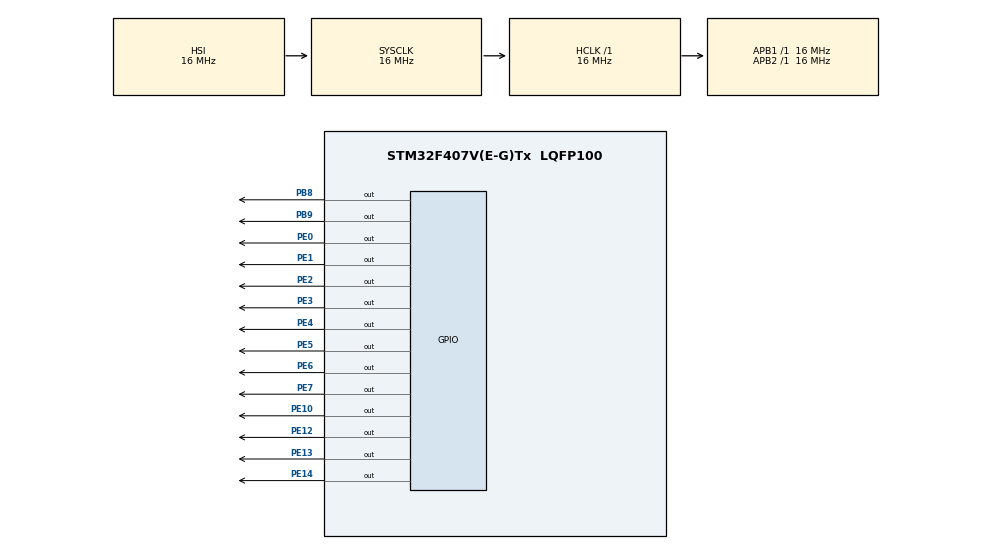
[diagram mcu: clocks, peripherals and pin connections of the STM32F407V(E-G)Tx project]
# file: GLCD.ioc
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Mcu.Family=STM32F4
Mcu.Name=STM32F407V(E-G)Tx
Mcu.Package=LQFP100
NVIC.PriorityGroup=NVIC_PRIORITYGROUP_4
PB8.Signal=GPIO_Output
PB9.Signal=GPIO_Output
PE0.Signal=GPIO_Output
PE1.Signal=GPIO_Output
PE10.Signal=GPIO_Output
PE12.Signal=GPIO_Output
PE13.Signal=GPIO_Output
PE14.Signal=GPIO_Output
PE2.Signal=GPIO_Output
PE3.Signal=GPIO_Output
PE4.Signal=GPIO_Output
PE5.Signal=GPIO_Output
PE6.Signal=GPIO_Output
PE7.Signal=GPIO_Output
PH0-OSC_IN.Mode=HSE-External-Oscillator
PH0-OSC_IN.Signal=RCC_OSC_IN
PH1-OSC_OUT.Mode=HSE-External-Oscillator
PH1-OSC_OUT.Signal=RCC_OSC_OUT
ProjectManager.HeapSize=0x200
ProjectManager.StackSize=0x400
ProjectManager.TargetToolchain=MDK-ARM V5.32
RCC.AHBFreq_Value=16000000
RCC.APB1Freq_Value=16000000
RCC.APB2Freq_Value=16000000
RCC.CortexFreq_Value=16000000
RCC.HSE_VALUE=8000000
RCC.HSI_VALUE=16000000
RCC.LSE_VALUE=32768
RCC.SYSCLKFreq_VALUE=16000000
RCC.VCOOutputFreq_Value=192000000
board=custom

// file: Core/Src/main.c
/* USER CODE BEGIN Header */
/**
 ******************************************************************************
 * @file           : main.c
 * @brief          : Main program body
 ******************************************************************************
 * @attention
 *
 * Copyright (c) 2025 STMicroelectronics.
 * All rights reserved.
 *
 * This software is licensed under terms that can be found in the LICENSE file
 * in the root directory of this software component.
 * If no LICENSE file comes with this software, it is provided AS-IS.
 *
 ******************************************************************************
 */
/* USER CODE END Header */
#include "main.h"

/* USER CODE BEGIN Includes */
#include "delay_fun.h"
#include "glcd2.h"

/* USER CODE END Includes */

/* USER CODE BEGIN PV */
extern const char img[1024];
extern const char img1[1024];
extern const char img2[1024];
extern const char img3[1024];
/* USER CODE END PV */

void SystemClock_Config(void);
static void MX_GPIO_Init(void);

int main(void)
{

	/* MCU Configuration--------------------------------------------------------*/

	/* Reset of all peripherals, Initializes the Flash interface and the Systick. */
	HAL_Init();

	/* Configure the system clock */
	SystemClock_Config();

	/* Initialize all configured peripherals */
	MX_GPIO_Init();
	/* USER CODE BEGIN 2 */
	TIM6Config();
	GLCD_Init();
	/* Initialize GLCD */
	GLCD_ClearAll();
	/* Clear all GLCD display */
	GLCD_String(0, "Microlab STM32f407 1403");
	/* Print String on 0th page of display
	 */
	HAL_Delay(2000);
	/* USER CODE END 2 */

	/* Infinite loop */
	/* USER CODE BEGIN WHILE */
	while (1)
	{
		// GLCD_Image(img);
		// HAL_Delay(500);
		// GLCD_Image(img1);
		// HAL_Delay(500);
		// GLCD_Image(img2);
		// HAL_Delay(500);
    GLCD_Image(img3);
		HAL_Delay(500);
		/* USER CODE END WHILE */

	}
}

void SystemClock_Config(void)
{
	RCC_OscInitTypeDef RCC_OscInitStruct = { 0 };
	RCC_ClkInitTypeDef RCC_ClkInitStruct = { 0 };

	/** Configure the main internal regulator output voltage
	 */
	__HAL_RCC_PWR_CLK_ENABLE();
	__HAL_PWR_VOLTAGESCALING_CONFIG(PWR_REGULATOR_VOLTAGE_SCALE1);

	/** Initializes the RCC Oscillators according to the specified parameters
	 * in the RCC_OscInitTypeDef structure.
	 */
	RCC_OscInitStruct.OscillatorType = RCC_OSCILLATORTYPE_HSI;
	RCC_OscInitStruct.HSIState = RCC_HSI_ON;
	RCC_OscInitStruct.HSICalibrationValue = RCC_HSICALIBRATION_DEFAULT;
	RCC_OscInitStruct.PLL.PLLState = RCC_PLL_NONE;
	if (HAL_RCC_OscConfig(&RCC_OscInitStruct) != HAL_OK)
	{
		Error_Handler();
	}

	/** Initializes the CPU, AHB and APB buses clocks
	 */
	RCC_ClkInitStruct.ClockType = RCC_CLOCKTYPE_HCLK | RCC_CLOCKTYPE_SYSCLK
		| RCC_CLOCKTYPE_PCLK1 | RCC_CLOCKTYPE_PCLK2;
	RCC_ClkInitStruct.SYSCLKSource = RCC_SYSCLKSOURCE_HSI;
	RCC_ClkInitStruct.AHBCLKDivider = RCC_SYSCLK_DIV1;
	RCC_ClkInitStruct.APB1CLKDivider = RCC_HCLK_DIV1;
	RCC_ClkInitStruct.APB2CLKDivider = RCC_HCLK_DIV1;

	if (HAL_RCC_ClockConfig(&RCC_ClkInitStruct, FLASH_LATENCY_0) != HAL_OK)
	{
		Error_Handler();
	}
}

static void MX_GPIO_Init(void)
{
	GPIO_InitTypeDef GPIO_InitStruct = { 0 };

	/* GPIO Ports Clock Enable */
	__HAL_RCC_GPIOE_CLK_ENABLE();
	__HAL_RCC_GPIOH_CLK_ENABLE();
	__HAL_RCC_GPIOB_CLK_ENABLE();

	/*Configure GPIO pin Output Level */
	HAL_GPIO_WritePin(GPIOE, GPIO_PIN_2 | GPIO_PIN_3 | GPIO_PIN_4 | GPIO_PIN_5 | GPIO_PIN_6 | GPIO_PIN_7 | GPIO_PIN_10 | GPIO_PIN_12 | GPIO_PIN_13 | GPIO_PIN_14 | GPIO_PIN_0 | GPIO_PIN_1, GPIO_PIN_RESET);

	/*Configure GPIO pin Output Level */
	HAL_GPIO_WritePin(GPIOB, GPIO_PIN_8 | GPIO_PIN_9, GPIO_PIN_RESET);

	/*Configure GPIO pins : PE2 PE3 PE4 PE5
							 PE6 PE7 PE10 PE12
							 PE13 PE14 PE0 PE1 */
	GPIO_InitStruct.Pin = GPIO_PIN_2 | GPIO_PIN_3 | GPIO_PIN_4 | GPIO_PIN_5
		| GPIO_PIN_6 | GPIO_PIN_7 | GPIO_PIN_10 | GPIO_PIN_12
		| GPIO_PIN_13 | GPIO_PIN_14 | GPIO_PIN_0 | GPIO_PIN_1;
	GPIO_InitStruct.Mode = GPIO_MODE_OUTPUT_PP;
	GPIO_InitStruct.Pull = GPIO_NOPULL;
	GPIO_InitStruct.Speed = GPIO_SPEED_FREQ_LOW;
	HAL_GPIO_Init(GPIOE, &GPIO_InitStruct);

	/*Configure GPIO pins : PB8 PB9 */
	GPIO_InitStruct.Pin = GPIO_PIN_8 | GPIO_PIN_9;
	GPIO_InitStruct.Mode = GPIO_MODE_OUTPUT_PP;
	GPIO_InitStruct.Pull = GPIO_NOPULL;
	GPIO_InitStruct.Speed = GPIO_SPEED_FREQ_LOW;
	HAL_GPIO_Init(GPIOB, &GPIO_InitStruct);
}

void Error_Handler(void)
{
	__disable_irq();
	while (1)
	{
	}
}
